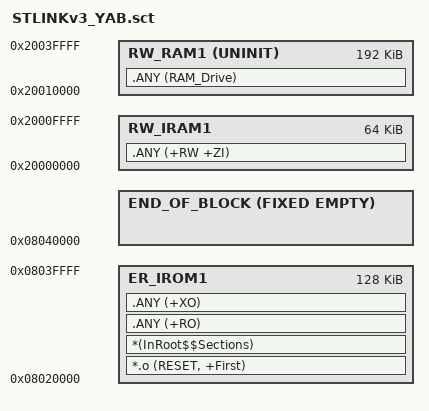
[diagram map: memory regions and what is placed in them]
; *************************************************************
; *** Scatter-Loading Description File for STLINKv3_YAB     ***
; *** Modified by RadioOperator   2020-07-23                ***
; *************************************************************

LR_IROM1 0x08020000 0x00020000  {    ; load region size_region
  ER_IROM1 0x08020000 0x00020000  {  ; load address = execution address
   *.o (RESET, +First)
   *(InRoot$$Sections)
   .ANY (+RO)
   .ANY (+XO)
  }
  RW_RAM1 0x20010000 UNINIT 0x00030000  {  ; MSC RAM drive
   .ANY (RAM_Drive)
  }
  RW_IRAM1 0x20000000 0x00010000  {
   .ANY (+RW +ZI)
  }
  END_OF_BLOCK 0x08040000 FIXED EMPTY 0x0 {} ; dummy area to fill 0xFF
}
